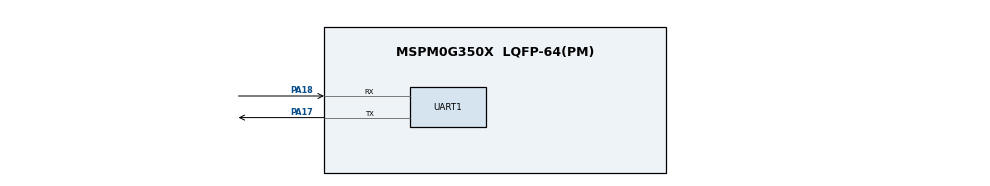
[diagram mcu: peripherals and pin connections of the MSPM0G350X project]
/**
 * @cliArgs --device "MSPM0G350X" --part "Default" --package "LQFP-64(PM)" --product "mspm0_sdk@2.02.00.05"
 * @versions {"tool":"1.24.0+4150"}
 */

/**
 * Import the modules used in this configuration.
 */
const GPIO    = scripting.addModule("/ti/driverlib/GPIO", {}, false);
const GPIO1   = GPIO.addInstance();
const SYSCTL  = scripting.addModule("/ti/driverlib/SYSCTL");
const SYSTICK = scripting.addModule("/ti/driverlib/SYSTICK");
const UART    = scripting.addModule("/ti/driverlib/UART", {}, false);
const UART1   = UART.addInstance();

/**
 * Write custom configuration values to the imported modules.
 */
const gate7  = system.clockTree["MFCLKGATE"];
gate7.enable = true;

GPIO1.port                          = "PORTA";
GPIO1.$name                         = "LED1";
GPIO1.associatedPins[0].assignedPin = "14";
GPIO1.associatedPins[0].$name       = "PIN_14";

const Board = scripting.addModule("/ti/driverlib/Board", {}, false);

SYSCTL.forceDefaultClkConfig = true;
SYSCTL.clockTreeEn           = true;

SYSTICK.periodEnable    = true;
SYSTICK.period          = 32000;
SYSTICK.interruptEnable = true;
SYSTICK.systickEnable   = true;

UART1.$name                            = "UART_1";
UART1.targetBaudRate                   = 115200;
UART1.peripheral.$assign               = "UART1";
UART1.peripheral.rxPin.$assign         = "PA18";
UART1.peripheral.txPin.$assign         = "PA17";
UART1.txPinConfig.direction            = scripting.forceWrite("OUTPUT");
UART1.txPinConfig.hideOutputInversion  = scripting.forceWrite(false);
UART1.txPinConfig.onlyInternalResistor = scripting.forceWrite(false);
UART1.txPinConfig.passedPeripheralType = scripting.forceWrite("Digital");
UART1.txPinConfig.$name                = "ti_driverlib_gpio_GPIOPinGeneric2";
UART1.rxPinConfig.hideOutputInversion  = scripting.forceWrite(false);
UART1.rxPinConfig.onlyInternalResistor = scripting.forceWrite(false);
UART1.rxPinConfig.passedPeripheralType = scripting.forceWrite("Digital");
UART1.rxPinConfig.$name                = "ti_driverlib_gpio_GPIOPinGeneric3";

/**
 * Pinmux solution for unlocked pins/peripherals. This ensures that minor changes to the automatic solver in a future
 * version of the tool will not impact the pinmux you originally saw.  These lines can be completely deleted in order to
 * re-solve from scratch.
 */
GPIO1.associatedPins[0].pin.$suggestSolution = "PA14";
Board.peripheral.$suggestSolution            = "DEBUGSS";
Board.peripheral.swclkPin.$suggestSolution   = "PA20";
Board.peripheral.swdioPin.$suggestSolution   = "PA19";
